# ATtiny1634 register map
Vendor: Atmel; File version: 1.0
CPU: other r0p0, little endian, no MPU, no FPU, 4 interrupt priority bits
Registers are 8-bit, read-write, reset 0x0 unless marked. A register's access mark holds for its fields unless they carry their own. Offsets are from the block's base; [hi:lo] are bit positions; {n}, {i} and the like mark numbered series.

## CPU — CPU Registers
Base 0x00800034
{0x0+i} GPIOR{i} (i=0..2) — General Purpose I/O Register {i}
0x1B CCP — Configuration Change Protection
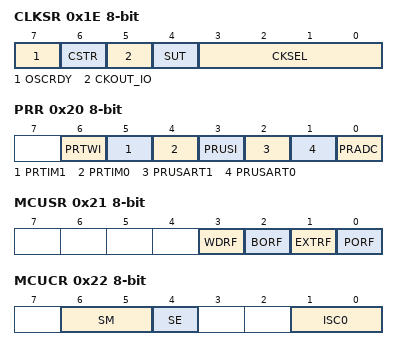
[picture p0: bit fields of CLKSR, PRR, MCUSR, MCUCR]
0x1E CLKSR — Clock Setting Register
  [7] OSCRDY — Oscillator Ready
  [6] CSTR — Clock Switch Trigger
  [5] CKOUT_IO — Clock Output (active low)
  [4] SUT — Start-up Time
  [3:0] CKSEL — Clock Select Bits
0x1F CLKPR — Clock Prescale Register
  [3:0] CLKPS — Clock Prescaler Select Bits
    0=1; 1=2; 2=4; 3=8; 4=16; 5=32; 6=64; 7=128; 8=256
0x20 PRR — Power Reduction Register
  [6] PRTWI — Power Reduction TWI
  [5] PRTIM1 — Power Reduction Timer/Counter1
  [4] PRTIM0 — Power Reduction Timer/Counter0
  [3] PRUSI — Power Reduction USI
  [2] PRUSART1 — Power Reduction USART1
  [1] PRUSART0 — Power Reduction USART0
  [0] PRADC — Power Reduction ADC
0x21 MCUSR — MCU Status Register
  [3] WDRF — Watchdog Reset Flag
  [2] BORF — Brown-out Reset Flag
  [1] EXTRF — External Reset Flag
  [0] PORF — Power-on reset flag
0x22 MCUCR — MCU Control Register
  [6:5] SM — Sleep Mode Select Bits
    0=IDLE; 1=ADC (ADC Noise Reduction (If Available)); 2=PDOWN (Power Down); 3=STDBY (Standby)
  [4] SE — Sleep Enable
  [1:0] ISC0 — Interrupt Sense Control 0 bits
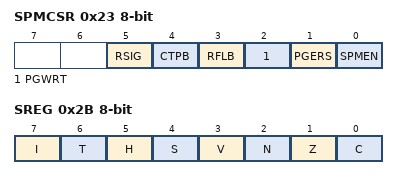
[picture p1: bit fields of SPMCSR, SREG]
0x23 SPMCSR — Store Program Memory Control and Status Register (read-only for debugger)
  [5] RSIG — Read Device Signature Imprint Table
  [4] CTPB — Clear Temporary Page Buffer
  [3] RFLB — Read Fuse and Lock Bits
  [2] PGWRT — Page Write
  [1] PGERS — Page Erase
  [0] SPMEN — Store program Memory Enable
0x29 SP 16-bit (reset mask 0xFF) — Stack Pointer
0x2B SREG — Status Register
  [7] I — Global Interrupt Enable
  [6] T — Bit Copy Storage
  [5] H — Half Carry Flag
  [4] S — Sign Bit
  [3] V — Two's Complement Overflow Flag
  [2] N — Negative Flag
  [1] Z — Zero Flag
  [0] C — Carry Flag
0x2F OSCCAL0 — Oscillator Calibration Value (read-only for debugger)
0x30 OSCTCAL0A
0x31 OSCTCAL0B
0x32 OSCCAL1

## EEPROM
Base 0x0080003C
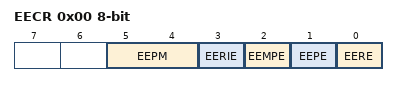
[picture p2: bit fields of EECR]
0x00 EECR — EEPROM Control Register
  [5:4] EEPM — EEPROM Programming Mode Bits
    0=ERASE_AND_WRITE_IN_ONE_OPERATION; 1=ERASE_ONLY; 2=WRITE_ONLY
  [3] EERIE — EEProm Ready Interrupt Enable
  [2] EEMPE — EEPROM Master Write Enable
  [1] EEPE — EEPROM Write Enable
  [0] EERE — EEPROM Read Enable
0x01 EEDR — EEPROM Data Register
0x02 EEAR 16-bit (reset mask 0xFF) — EEPROM Read/Write Access

## EXINT — External Interrupts
Base 0x00800047
0x00 PCMSK0 — Pin Change Mask Register 0
  [7:0] PCINT — Pin Change Enable Masks
0x01 PCMSK1 — Pin Change Mask Register 1
  [3:0] PCINT — Pin Change Enable Masks
0x02 PCMSK2 — Pin Change Mask Register 2
  [5:0] PCINT — Pin Change Enable Masks
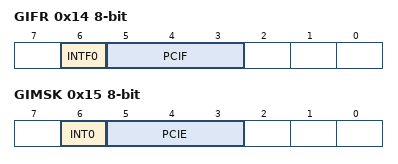
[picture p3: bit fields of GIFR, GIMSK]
0x14 GIFR — General Interrupt Flag Register
  [6] INTF0 — External Interrupt Flag 0
  [5:3] PCIF — Pin Change Interrupt Flags
0x15 GIMSK — General Interrupt Mask Register
  [6] INT0 — External Interrupt Request 0 Enable
  [5:3] PCIE — Pin Change Interrupt Enables

## PORTA — I/O Port
Base 0x0080002F
0x00 PINA — Port A Input Pins
0x01 DDRA — Data Direction Register, Port A
0x02 PORTA — Port A Data Register
0x03 PUEA — Pull-up Enable Control Register
  [7:0] PUEA — Pull-up Enable Control bit
0x04 PORTCR — Port Control Register
  [0] BBMA — Break-Before-Make Mode Enable

## PORTB — I/O Port
Base 0x0080002B
0x00 PINB — Port B Data register
0x01 DDRB — Data Direction Register, Port B
0x02 PORTB — Input Pins, Port B
0x03 PUEB — Pull-up Enable Control Register
  [3:0] PUEB — Pull-up Enable Control bit
0x08 PORTCR — Port Control Register
  [1] BBMB — Break-Before-Make Mode Enable

## PORTC — I/O Port
Base 0x00800027
0x00 PINC — Port C Input Pins
0x01 DDRC — Data Direction Register, Port C
0x02 PORTC — Port C Data Register
0x03 PUEC — Pull-up Enable Control Register
  [5:0] PUEC — Pull-up Enable Control bit
0x0C PORTCR — Port Control Register
  [2] BBMC — Break-Before-Make Mode Enable
